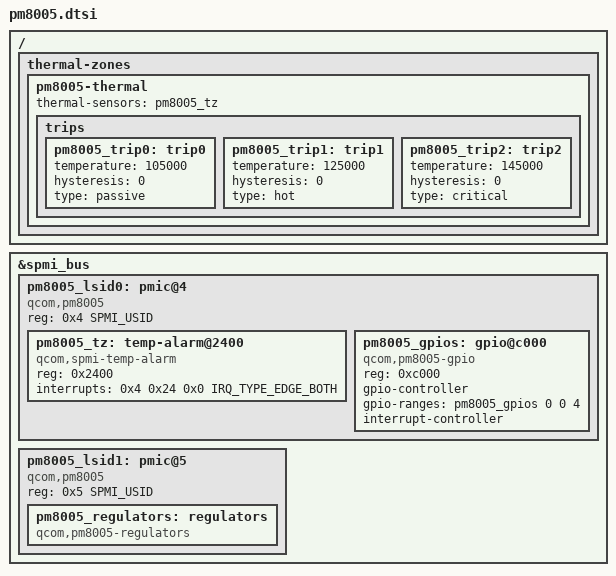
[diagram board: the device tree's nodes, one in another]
// SPDX-License-Identifier: (GPL-2.0+ OR MIT)
/* Copyright 2018 Google LLC. */

#include <dt-bindings/spmi/spmi.h>
#include <dt-bindings/interrupt-controller/irq.h>

/ {
	thermal-zones {
		pm8005-thermal {
			thermal-sensors = <&pm8005_tz>;

			trips {
				pm8005_trip0: trip0 {
					temperature = <105000>;
					hysteresis = <0>;
					type = "passive";
				};

				pm8005_trip1: trip1 {
					temperature = <125000>;
					hysteresis = <0>;
					type = "hot";
				};

				pm8005_trip2: trip2 {
					temperature = <145000>;
					hysteresis = <0>;
					type = "critical";
				};
			};
		};
	};
};

&spmi_bus {
	pm8005_lsid0: pmic@4 {
		compatible = "qcom,pm8005", "qcom,spmi-pmic";
		reg = <0x4 SPMI_USID>;
		#address-cells = <1>;
		#size-cells = <0>;

		pm8005_tz: temp-alarm@2400 {
			compatible = "qcom,spmi-temp-alarm";
			reg = <0x2400>;
			interrupts = <0x4 0x24 0x0 IRQ_TYPE_EDGE_BOTH>;
			#thermal-sensor-cells = <0>;
		};

		pm8005_gpios: gpio@c000 {
			compatible = "qcom,pm8005-gpio", "qcom,spmi-gpio";
			reg = <0xc000>;
			gpio-controller;
			gpio-ranges = <&pm8005_gpios 0 0 4>;
			#gpio-cells = <2>;
			interrupt-controller;
			#interrupt-cells = <2>;
		};

	};

	pm8005_lsid1: pmic@5 {
		compatible = "qcom,pm8005", "qcom,spmi-pmic";
		reg = <0x5 SPMI_USID>;
		#address-cells = <1>;
		#size-cells = <0>;

		pm8005_regulators: regulators {
			compatible = "qcom,pm8005-regulators";
		};
	};
};
